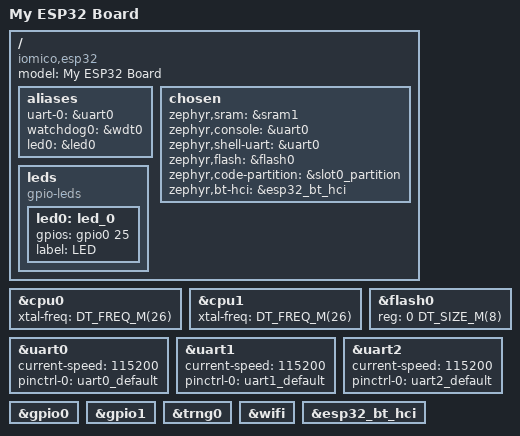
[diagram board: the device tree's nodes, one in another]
/*
 * Copyright (c) 2026 Iomico
 *
 * SPDX-License-Identifier: Apache-2.0
 */

/dts-v1/;

#include <espressif/esp32/esp32_d0wd_v3.dtsi>
#include "my_esp32_board-pinctrl.dtsi"
#include <espressif/partitions_0x1000_amp.dtsi>

/ {
	model = "My ESP32 Board";
	compatible = "iomico,esp32";

	aliases {
		uart-0 = &uart0;
		watchdog0 = &wdt0;
                led0 = &led0;
	};

	chosen {
		zephyr,sram = &sram1;
		zephyr,console = &uart0;
		zephyr,shell-uart = &uart0;
		zephyr,flash = &flash0;
		zephyr,code-partition = &slot0_partition;
		zephyr,bt-hci = &esp32_bt_hci;
	};

	leds {
		compatible = "gpio-leds";

		led0: led_0 {
			gpios = <&gpio0 25 GPIO_ACTIVE_HIGH>;
			label = "LED";
		};
	};

};

/*
 * CPU / XTAL
 *
 * Iomico ESP32 uses a 26 MHz crystal.
 */

&cpu0 {
	xtal-freq = <DT_FREQ_M(26)>;
};

&cpu1 {
	xtal-freq = <DT_FREQ_M(26)>;
};

/*
 * Flash
 *
 * Iomico ESP32 uses 4 MiB external flash.
 */

&flash0 {
	reg = <0 DT_SIZE_M(8)>;
	status = "okay";
};

/*
 * UART
 */

&uart0 {
	status = "okay";
	current-speed = <115200>;
	pinctrl-0 = <&uart0_default>;
	pinctrl-names = "default";
};

&uart1 {
	current-speed = <115200>;
	pinctrl-0 = <&uart1_default>;
	pinctrl-names = "default";
};

&uart2 {
	current-speed = <115200>;
	pinctrl-0 = <&uart2_default>;
	pinctrl-names = "default";
};

/*
 * GPIO
 */

&gpio0 {
	status = "okay";
};

&gpio1 {
	status = "okay";
};

/*
 * Random number generator
 */

&trng0 {
	status = "okay";
};

/*
 * WiFi
 */

&wifi {
	status = "okay";
};

/*
 * Bluetooth
 */

&esp32_bt_hci {
	status = "okay";
};
